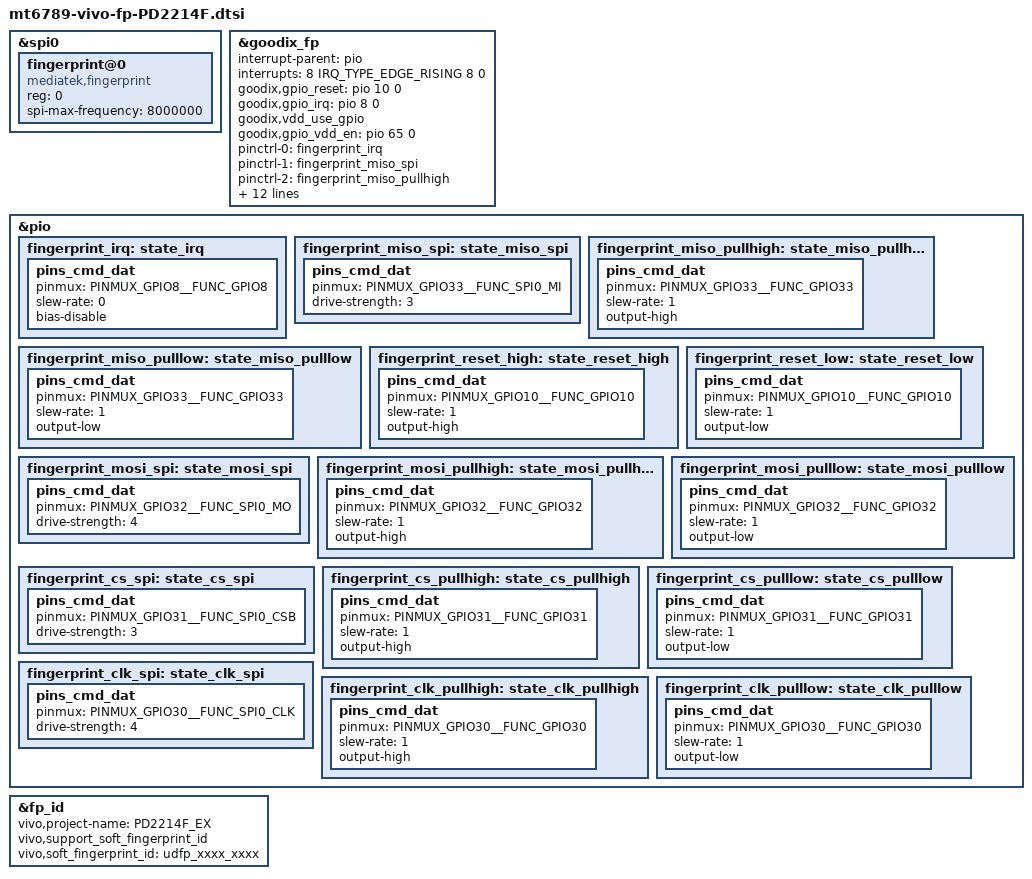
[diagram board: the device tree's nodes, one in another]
&spi0 {
	#address-cells = <1>;
	#size-cells = <0>;
	fingerprint@0 {
		compatible = "mediatek,fingerprint";
		reg = <0>;
		spi-max-frequency = <8000000>;
		// netlink-event = <30>;
		// vfp-supply = <&mt_pmic_vtp_ldo_reg>;
		status = "okay";
	};
};

&goodix_fp {
	interrupt-parent = <&pio>;
	interrupts = <8 IRQ_TYPE_EDGE_RISING 8 0>;

	goodix,gpio_reset = <&pio 10 0>;
	goodix,gpio_irq = <&pio 8 0>;
	//vdd 3.3v config
	goodix,vdd_use_gpio;
	goodix,gpio_vdd_en = <&pio 65 0>;
	//goodix,vdd_use_pmic;
	//vdd-supply = <&mt_pmic_vtp_ldo_reg>;

	//vddio 1.8v config
	//goodix,vddio_use_gpio;
	//goodix,gpio_vddio_en = <&pio 126 0>;
	//goodix,vddio_use_pmic;
	//vddio-supply = <&mt_pmic_vfp_ldo_reg>;
	status = "okay";

	pinctrl-names = "fingerprint_irq", "miso_spi", "miso_pullhigh", "miso_pulllow", "reset_high", "reset_low","mosi_spi","mosi_pullhigh","mosi_pulllow","cs_spi","cs_pullhigh","cs_pulllow","clk_spi","clk_pullhigh","clk_pulllow";
	pinctrl-0 = <&fingerprint_irq>;
	pinctrl-1 = <&fingerprint_miso_spi>;
	pinctrl-2 = <&fingerprint_miso_pullhigh>;
	pinctrl-3 = <&fingerprint_miso_pulllow>;
	pinctrl-4 = <&fingerprint_reset_high>;
	pinctrl-5 = <&fingerprint_reset_low>;
	pinctrl-6 = <&fingerprint_mosi_spi>;
	pinctrl-7 = <&fingerprint_mosi_pullhigh>;
	pinctrl-8 = <&fingerprint_mosi_pulllow>;
	pinctrl-9 = <&fingerprint_cs_spi>;
	pinctrl-10 = <&fingerprint_cs_pullhigh>;
	pinctrl-11 = <&fingerprint_cs_pulllow>;
	pinctrl-12 = <&fingerprint_clk_spi>;
	pinctrl-13 = <&fingerprint_clk_pullhigh>;
	pinctrl-14 = <&fingerprint_clk_pulllow>;
};

&pio {
	fingerprint_irq: state_irq {
		pins_cmd_dat {
			pinmux = <PINMUX_GPIO8__FUNC_GPIO8>;
			slew-rate = <0>;
			bias-disable;
		};
	};

	fingerprint_miso_spi: state_miso_spi {
		pins_cmd_dat {
			pinmux = <PINMUX_GPIO33__FUNC_SPI0_MI>;
			drive-strength = <3>;
		};
	};

	fingerprint_miso_pullhigh: state_miso_pullhigh {
		pins_cmd_dat {
			pinmux = <PINMUX_GPIO33__FUNC_GPIO33>;
			slew-rate = <1>;
			output-high;
		};
	};

	fingerprint_miso_pulllow: state_miso_pulllow {
		pins_cmd_dat {
			pinmux = <PINMUX_GPIO33__FUNC_GPIO33>;
			slew-rate = <1>;
			output-low;
		};
	};

	fingerprint_reset_high: state_reset_high {
		pins_cmd_dat {
			pinmux = <PINMUX_GPIO10__FUNC_GPIO10>;
			slew-rate = <1>;
			output-high;
		};
	};

	fingerprint_reset_low: state_reset_low {
		pins_cmd_dat {
			pinmux = <PINMUX_GPIO10__FUNC_GPIO10>;
			slew-rate = <1>;
			output-low;
		};
	};

	fingerprint_mosi_spi: state_mosi_spi {
		pins_cmd_dat {
			pinmux = <PINMUX_GPIO32__FUNC_SPI0_MO>;
			drive-strength = <4>;
		};
	};

	fingerprint_mosi_pullhigh: state_mosi_pullhigh {
		pins_cmd_dat {
			pinmux = <PINMUX_GPIO32__FUNC_GPIO32>;
			slew-rate = <1>;
			output-high;
		};
	};

	fingerprint_mosi_pulllow: state_mosi_pulllow {
		pins_cmd_dat {
			pinmux = <PINMUX_GPIO32__FUNC_GPIO32>;
			slew-rate = <1>;
			output-low;
		};
	};

	fingerprint_cs_spi: state_cs_spi {
		pins_cmd_dat {
			pinmux = <PINMUX_GPIO31__FUNC_SPI0_CSB>;
			drive-strength = <3>;
		};
	};

	fingerprint_cs_pullhigh: state_cs_pullhigh {
		pins_cmd_dat {
			pinmux = <PINMUX_GPIO31__FUNC_GPIO31>;
			slew-rate = <1>;
			output-high;
		};
	};

	fingerprint_cs_pulllow: state_cs_pulllow {
		pins_cmd_dat {
			pinmux = <PINMUX_GPIO31__FUNC_GPIO31>;
			slew-rate = <1>;
			output-low;
		};
	};

	fingerprint_clk_spi: state_clk_spi {
		pins_cmd_dat {
			pinmux = <PINMUX_GPIO30__FUNC_SPI0_CLK>;
			drive-strength = <4>;
		};
	};
	fingerprint_clk_pullhigh: state_clk_pullhigh {
		pins_cmd_dat {
			pinmux = <PINMUX_GPIO30__FUNC_GPIO30>;
			slew-rate = <1>;
			output-high;
		};
	};

	fingerprint_clk_pulllow: state_clk_pulllow {
		pins_cmd_dat {
			pinmux = <PINMUX_GPIO30__FUNC_GPIO30>;
			slew-rate = <1>;
			output-low;
		};
	};
};

&fp_id {
	status="okay";
	vivo,project-name = "PD2214F_EX";
	vivo,support_soft_fingerprint_id;
	vivo,soft_fingerprint_id="udfp_xxxx_xxxx";
	// fp_id,gpios= <&pio 20 0>;
	// pinctrl-names = "fp_gpio_pull_up",
	// 				"fp_gpio_pull_down";
	// pinctrl-0 = <&fp_id_gpio_up>;
	// pinctrl-1 = <&fp_id_gpio_down>;
};
